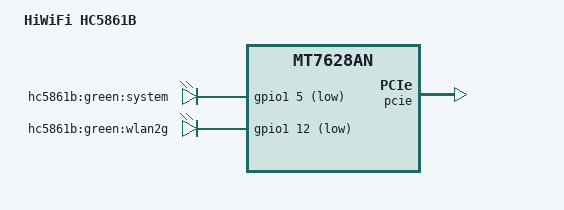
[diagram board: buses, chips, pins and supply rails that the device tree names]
// SPDX-License-Identifier: GPL-2.0-or-later OR MIT
/dts-v1/;

#include "HC5X61A.dtsi"

/ {
	compatible = "hiwifi,hc5861b", "mediatek,mt7628an-soc";
	model = "HiWiFi HC5861B";

	leds {
		compatible = "gpio-leds";

		led_system: system {
			label = "hc5861b:green:system";
			gpios = <&gpio1 5 GPIO_ACTIVE_LOW>;
		};

		wlan2g {
			label = "hc5861b:green:wlan2g";
			gpios = <&gpio1 12 GPIO_ACTIVE_LOW>;
			linux,default-trigger = "phy0tpt";
		};
	};
};

&ehci {
	status = "disabled";
};

&ohci {
	status = "disabled";
};

&pcie {
	status = "okay";
};

&pcie0 {
	wifi@0,0 {
		reg = <0x0000 0 0 0 0>;
		mediatek,mtd-eeprom = <&factory 0x8000>;
		mtd-mac-address = <&factory 0x2e>;
		ieee80211-freq-limit = <5000000 6000000>;

		led {
			led-sources = <2>;
			led-active-low;
		};
	};
};
